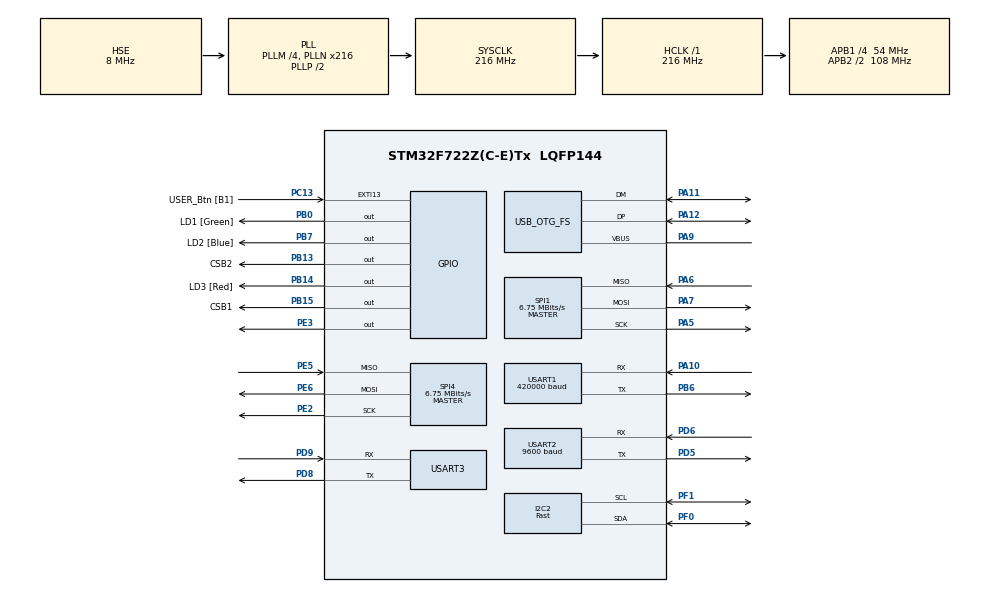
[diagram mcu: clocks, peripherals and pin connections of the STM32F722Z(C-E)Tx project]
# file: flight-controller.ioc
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CORTEX_M7.AccessPermission_S-Cortex_Memory_Protection_Unit_Region1_Settings_S=MPU_REGION_FULL_ACCESS
CORTEX_M7.BaseAddress_S-Cortex_Memory_Protection_Unit_Region1_Settings_S=0x2003C000
CORTEX_M7.CPU_DCache=Enabled
CORTEX_M7.CPU_ICache=Enabled
CORTEX_M7.DisableExec_S-Cortex_Memory_Protection_Unit_Region1_Settings_S=MPU_INSTRUCTION_ACCESS_DISABLE
CORTEX_M7.Enable_S-Cortex_Memory_Protection_Unit_Region1_Settings_S=MPU_REGION_ENABLE
CORTEX_M7.Enable_S-Cortex_Memory_Protection_Unit_Region2_Settings_S=__NULL
CORTEX_M7.IsShareable_S-Cortex_Memory_Protection_Unit_Region1_Settings_S=MPU_ACCESS_SHAREABLE
CORTEX_M7.Size_S-Cortex_Memory_Protection_Unit_Region1_Settings_S=MPU_REGION_SIZE_16KB
CORTEX_M7.TypeExtField_S-Cortex_Memory_Protection_Unit_Region1_Settings_S=MPU_TEX_LEVEL1
CORTEX_M7.default_mode_Activation=1
Dma.I2C2_RX.4.Direction=DMA_PERIPH_TO_MEMORY
Dma.I2C2_RX.4.FIFOMode=DMA_FIFOMODE_DISABLE
Dma.I2C2_RX.4.Instance=DMA1_Stream2
Dma.I2C2_RX.4.MemDataAlignment=DMA_MDATAALIGN_BYTE
Dma.I2C2_RX.4.MemInc=DMA_MINC_ENABLE
Dma.I2C2_RX.4.Mode=DMA_NORMAL
Dma.I2C2_RX.4.PeriphDataAlignment=DMA_PDATAALIGN_BYTE
Dma.I2C2_RX.4.PeriphInc=DMA_PINC_DISABLE
Dma.I2C2_RX.4.Priority=DMA_PRIORITY_LOW
Dma.I2C2_TX.5.Direction=DMA_MEMORY_TO_PERIPH
Dma.I2C2_TX.5.FIFOMode=DMA_FIFOMODE_DISABLE
Dma.I2C2_TX.5.Instance=DMA1_Stream7
Dma.I2C2_TX.5.MemDataAlignment=DMA_MDATAALIGN_BYTE
Dma.I2C2_TX.5.MemInc=DMA_MINC_ENABLE
Dma.I2C2_TX.5.Mode=DMA_NORMAL
Dma.I2C2_TX.5.PeriphDataAlignment=DMA_PDATAALIGN_BYTE
Dma.I2C2_TX.5.PeriphInc=DMA_PINC_DISABLE
Dma.I2C2_TX.5.Priority=DMA_PRIORITY_LOW
Dma.Request0=SPI1_RX
Dma.Request1=SPI1_TX
Dma.Request2=USART2_RX
Dma.Request3=USART2_TX
Dma.Request4=I2C2_RX
Dma.Request5=I2C2_TX
Dma.Request6=USART1_RX
Dma.SPI1_RX.0.Direction=DMA_PERIPH_TO_MEMORY
Dma.SPI1_RX.0.FIFOMode=DMA_FIFOMODE_DISABLE
Dma.SPI1_RX.0.Instance=DMA2_Stream0
Dma.SPI1_RX.0.MemDataAlignment=DMA_MDATAALIGN_BYTE
Dma.SPI1_RX.0.MemInc=DMA_MINC_ENABLE
Dma.SPI1_RX.0.Mode=DMA_NORMAL
Dma.SPI1_RX.0.PeriphDataAlignment=DMA_PDATAALIGN_BYTE
Dma.SPI1_RX.0.PeriphInc=DMA_PINC_DISABLE
Dma.SPI1_RX.0.Priority=DMA_PRIORITY_LOW
Dma.SPI1_TX.1.Direction=DMA_MEMORY_TO_PERIPH
Dma.SPI1_TX.1.FIFOMode=DMA_FIFOMODE_DISABLE
Dma.SPI1_TX.1.Instance=DMA2_Stream3
Dma.SPI1_TX.1.MemDataAlignment=DMA_MDATAALIGN_BYTE
Dma.SPI1_TX.1.MemInc=DMA_MINC_ENABLE
Dma.SPI1_TX.1.Mode=DMA_NORMAL
Dma.SPI1_TX.1.PeriphDataAlignment=DMA_PDATAALIGN_BYTE
Dma.SPI1_TX.1.PeriphInc=DMA_PINC_DISABLE
Dma.SPI1_TX.1.Priority=DMA_PRIORITY_LOW
Dma.USART1_RX.6.Direction=DMA_PERIPH_TO_MEMORY
Dma.USART1_RX.6.FIFOMode=DMA_FIFOMODE_DISABLE
Dma.USART1_RX.6.Instance=DMA2_Stream2
Dma.USART1_RX.6.MemDataAlignment=DMA_MDATAALIGN_BYTE
Dma.USART1_RX.6.MemInc=DMA_MINC_ENABLE
Dma.USART1_RX.6.Mode=DMA_CIRCULAR
Dma.USART1_RX.6.PeriphDataAlignment=DMA_PDATAALIGN_BYTE
Dma.USART1_RX.6.PeriphInc=DMA_PINC_DISABLE
Dma.USART1_RX.6.Priority=DMA_PRIORITY_LOW
Dma.USART2_RX.2.Direction=DMA_PERIPH_TO_MEMORY
Dma.USART2_RX.2.FIFOMode=DMA_FIFOMODE_DISABLE
Dma.USART2_RX.2.Instance=DMA1_Stream5
Dma.USART2_RX.2.MemDataAlignment=DMA_MDATAALIGN_BYTE
Dma.USART2_RX.2.MemInc=DMA_MINC_ENABLE
Dma.USART2_RX.2.Mode=DMA_CIRCULAR
Dma.USART2_RX.2.PeriphDataAlignment=DMA_PDATAALIGN_BYTE
Dma.USART2_RX.2.PeriphInc=DMA_PINC_DISABLE
Dma.USART2_RX.2.Priority=DMA_PRIORITY_LOW
Dma.USART2_TX.3.Direction=DMA_MEMORY_TO_PERIPH
Dma.USART2_TX.3.FIFOMode=DMA_FIFOMODE_DISABLE
Dma.USART2_TX.3.Instance=DMA1_Stream6
Dma.USART2_TX.3.MemDataAlignment=DMA_MDATAALIGN_BYTE
Dma.USART2_TX.3.MemInc=DMA_MINC_ENABLE
Dma.USART2_TX.3.Mode=DMA_NORMAL
Dma.USART2_TX.3.PeriphDataAlignment=DMA_PDATAALIGN_BYTE
Dma.USART2_TX.3.PeriphInc=DMA_PINC_DISABLE
Dma.USART2_TX.3.Priority=DMA_PRIORITY_LOW
I2C2.I2C_Speed_Mode=I2C_Fast
I2C2.Timing=0x6000030D
Mcu.Family=STM32F7
Mcu.Name=STM32F722Z(C-E)Tx
Mcu.Package=LQFP144
NVIC.DMA1_Stream2_IRQn=true\:5\:0\:true\:false\:true\:false\:true\:true
NVIC.DMA1_Stream5_IRQn=true\:5\:0\:true\:false\:true\:false\:true\:true
NVIC.DMA1_Stream6_IRQn=true\:5\:0\:true\:false\:true\:false\:true\:true
NVIC.DMA1_Stream7_IRQn=true\:0\:0\:false\:false\:true\:false\:true\:true
NVIC.DMA2_Stream0_IRQn=true\:5\:0\:true\:false\:true\:false\:true\:true
NVIC.DMA2_Stream2_IRQn=true\:5\:0\:true\:false\:true\:false\:true\:true
NVIC.DMA2_Stream3_IRQn=true\:5\:0\:true\:false\:true\:false\:true\:true
NVIC.I2C2_ER_IRQn=true\:5\:0\:true\:false\:true\:true\:true\:true
NVIC.I2C2_EV_IRQn=true\:5\:0\:true\:false\:true\:true\:true\:true
NVIC.OTG_FS_IRQn=true\:0\:0\:false\:false\:true\:false\:true\:true
NVIC.PriorityGroup=NVIC_PRIORITYGROUP_4
NVIC.SPI1_IRQn=true\:5\:0\:true\:false\:true\:true\:true\:true
NVIC.TIM6_DAC_IRQn=true\:15\:0\:false\:false\:true\:false\:true\:true
NVIC.TimeBase=TIM6_DAC_IRQn
NVIC.TimeBaseIP=TIM6
NVIC.USART1_IRQn=true\:5\:0\:true\:false\:true\:true\:true\:true
NVIC.USART2_IRQn=true\:5\:0\:true\:false\:true\:true\:true\:true
PA10.Mode=Asynchronous
PA10.Signal=USART1_RX
PA11.Mode=Device_Only
PA11.Signal=USB_OTG_FS_DM
PA12.Mode=Device_Only
PA12.Signal=USB_OTG_FS_DP
PA13.GPIO_Label=TMS
PA13.Mode=Serial_Wire
PA13.Signal=SYS_JTMS-SWDIO
PA14.GPIO_Label=TCK
PA14.Mode=Serial_Wire
PA14.Signal=SYS_JTCK-SWCLK
PA5.Mode=Full_Duplex_Master
PA5.Signal=SPI1_SCK
PA6.Mode=Full_Duplex_Master
PA6.Signal=SPI1_MISO
PA7.Mode=Full_Duplex_Master
PA7.Signal=SPI1_MOSI
PA9.Mode=Activate_VBUS
PA9.Signal=USB_OTG_FS_VBUS
PB0.GPIO_Label=LD1 [Green]
PB0.Signal=GPIO_Output
PB13.GPIO_Label=CSB2
PB13.GPIO_PuPd=GPIO_PULLUP
PB13.PinState=GPIO_PIN_RESET
PB13.Signal=GPIO_Output
PB14.GPIO_Label=LD3 [Red]
PB14.Signal=GPIO_Output
PB15.GPIO_Label=CSB1
PB15.GPIO_PuPd=GPIO_PULLUP
PB15.Signal=GPIO_Output
PB6.Mode=Asynchronous
PB6.Signal=USART1_TX
PB7.GPIO_Label=LD2 [Blue]
PB7.Signal=GPIO_Output
PC13.GPIO_Label=USER_Btn [B1]
PC13.Signal=GPXTI13
PC14-OSC32_IN.Mode=LSE-External-Oscillator
PC14-OSC32_IN.Signal=RCC_OSC32_IN
PC15-OSC32_OUT.Mode=LSE-External-Oscillator
PC15-OSC32_OUT.Signal=RCC_OSC32_OUT
PD5.Mode=Asynchronous
PD5.Signal=USART2_TX
PD6.Mode=Asynchronous
PD6.Signal=USART2_RX
PD8.Mode=Asynchronous
PD8.Signal=USART3_TX
PD9.Mode=Asynchronous
PD9.Signal=USART3_RX
PE2.Mode=Full_Duplex_Master
PE2.Signal=SPI4_SCK
PE3.Signal=GPIO_Output
PE5.Mode=Full_Duplex_Master
PE5.Signal=SPI4_MISO
PE6.Mode=Full_Duplex_Master
PE6.Signal=SPI4_MOSI
PF0.GPIO_Pu=GPIO_PULLUP
PF0.Mode=I2C
PF0.Signal=I2C2_SDA
PF1.GPIO_Pu=GPIO_PULLUP
PF1.Mode=I2C
PF1.Signal=I2C2_SCL
PH0-OSC_IN.GPIO_Label=MCO
PH0-OSC_IN.Mode=HSE-External-Clock-Source
PH0-OSC_IN.Signal=RCC_OSC_IN
PH1-OSC_OUT.Mode=HSE-External-Clock-Source
PH1-OSC_OUT.Signal=RCC_OSC_OUT
ProjectManager.HeapSize=0x200
ProjectManager.StackSize=0x400
ProjectManager.TargetToolchain=CMake
RCC.48MHZClocksFreq_Value=24000000
RCC.AHBFreq_Value=216000000
RCC.APB1CLKDivider=RCC_HCLK_DIV4
RCC.APB1Freq_Value=54000000
RCC.APB1TimFreq_Value=108000000
RCC.APB2CLKDivider=RCC_HCLK_DIV2
RCC.APB2Freq_Value=108000000
RCC.APB2TimFreq_Value=216000000
RCC.CortexFreq_Value=216000000
RCC.HCLKFreq_Value=216000000
RCC.HSE_VALUE=8000000
RCC.HSI_VALUE=16000000
RCC.PLLM=4
RCC.PLLMUL=RCC_PLL_MUL9
RCC.PLLN=216
RCC.PLLQ=9
RCC.PRESCALERUSB=RCC_USBCLKSOURCE_PLL_DIV1_5
RCC.SYSCLKFreq_VALUE=216000000
RCC.SYSCLKSource=RCC_SYSCLKSOURCE_PLLCLK
RCC.SYSCLKSourceVirtual=RCC_SYSCLKSOURCE_PLLCLK
RCC.USBFreq_Value=48000000
RCC.VCOOutputFreq_Value=432000000
SPI1.BaudRatePrescaler=SPI_BAUDRATEPRESCALER_16
SPI1.CalculateBaudRate=6.75 MBits/s
SPI1.DataSize=SPI_DATASIZE_8BIT
SPI1.Direction=SPI_DIRECTION_2LINES
SPI1.FirstBit=SPI_FIRSTBIT_MSB
SPI1.Mode=SPI_MODE_MASTER
SPI1.NSSPMode=SPI_NSS_PULSE_DISABLE
SPI1.VirtualType=VM_MASTER
SPI4.BaudRatePrescaler=SPI_BAUDRATEPRESCALER_16
SPI4.CalculateBaudRate=6.75 MBits/s
SPI4.DataSize=SPI_DATASIZE_8BIT
SPI4.Direction=SPI_DIRECTION_2LINES
SPI4.Mode=SPI_MODE_MASTER
SPI4.NSSPMode=SPI_NSS_PULSE_DISABLE
SPI4.VirtualType=VM_MASTER
USART1.BaudRate=420000
USART1.VirtualMode-Asynchronous=VM_ASYNC
USART2.BaudRate=9600
USART2.VirtualMode-Asynchronous=VM_ASYNC
USART3.VirtualMode-Asynchronous=VM_ASYNC
USB_DEVICE.CLASS_NAME_FS=CDC
USB_DEVICE.VirtualMode-CDC_FS=Cdc
USB_DEVICE.VirtualModeFS=Cdc_FS
USB_OTG_FS.VirtualMode=Device_Only
VP_SYS_VS_tim6.Mode=TIM6
VP_USB_DEVICE_VS_USB_DEVICE_CDC_FS.Mode=CDC_FS
board=NUCLEO-F722ZE

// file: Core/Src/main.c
/* USER CODE BEGIN Header */
/**
  ******************************************************************************
  * @file           : main.c
  * @brief          : Main program body
  ******************************************************************************
  * @attention
  *
  * Copyright (c) 2026 STMicroelectronics.
  * All rights reserved.
  *
  * This software is licensed under terms that can be found in the LICENSE file
  * in the root directory of this software component.
  * If no LICENSE file comes with this software, it is provided AS-IS.
  *
  ******************************************************************************
  */
/* USER CODE END Header */
#include "main.h"
#include "usb_device.h"

/* USER CODE BEGIN Includes */
#include "app_main.h"
#include "fc_types.h"
#include "pin_map.h"
/* USER CODE END Includes */

I2C_HandleTypeDef hi2c2;
DMA_HandleTypeDef hdma_i2c2_rx;
DMA_HandleTypeDef hdma_i2c2_tx;

SPI_HandleTypeDef hspi1;
SPI_HandleTypeDef hspi4;
DMA_HandleTypeDef hdma_spi1_rx;
DMA_HandleTypeDef hdma_spi1_tx;

UART_HandleTypeDef huart1;
UART_HandleTypeDef huart2;
UART_HandleTypeDef huart3;
DMA_HandleTypeDef hdma_usart1_rx;
DMA_HandleTypeDef hdma_usart2_rx;
DMA_HandleTypeDef hdma_usart2_tx;

/* USER CODE BEGIN PV */
static FC_Hw_t hw = {
  .hspi_imu = &hspi1,
  .hspi_bar = &hspi4,
  .hi2c_mag = &hi2c2,
  .huart_crsf = &huart1,
  .huart_gps = &huart2,
  .huart_print = &huart3,
};
/* USER CODE END PV */

void SystemClock_Config(void);
static void MPU_Config(void);
static void MX_GPIO_Init(void);
static void MX_DMA_Init(void);
static void MX_USART3_UART_Init(void);
static void MX_SPI1_Init(void);
static void MX_USART1_UART_Init(void);
static void MX_USART2_UART_Init(void);
static void MX_I2C2_Init(void);
static void MX_SPI4_Init(void);

int main(void)
{

  /* MPU Configuration--------------------------------------------------------*/
  MPU_Config();

  /* Enable the CPU Cache */

  /* Enable I-Cache---------------------------------------------------------*/
  SCB_EnableICache();

  /* Enable D-Cache---------------------------------------------------------*/
  SCB_EnableDCache();

  /* MCU Configuration--------------------------------------------------------*/

  /* Reset of all peripherals, Initializes the Flash interface and the Systick. */
  HAL_Init();

  /* Configure the system clock */
  SystemClock_Config();

  /* Initialize all configured peripherals */
  MX_GPIO_Init();
  MX_DMA_Init();
  MX_USART3_UART_Init();
  MX_SPI1_Init();
  MX_USART1_UART_Init();
  MX_USART2_UART_Init();
  MX_I2C2_Init();
  MX_SPI4_Init();
  MX_USB_DEVICE_Init();
  /* USER CODE BEGIN 2 */

  // Defining hardware peripherals for IMU
  if ( app_init(&hw) != FC_OK) Error_Handler() ;

  if ( app_start() != FC_OK) Error_Handler() ;
  /* USER CODE END 2 */

  /* Infinite loop */
  while (1)
  {

  }
}

void SystemClock_Config(void)
{
  RCC_OscInitTypeDef RCC_OscInitStruct = {0};
  RCC_ClkInitTypeDef RCC_ClkInitStruct = {0};

  /** Configure LSE Drive Capability
  */
  HAL_PWR_EnableBkUpAccess();

  /** Configure the main internal regulator output voltage
  */
  __HAL_RCC_PWR_CLK_ENABLE();
  __HAL_PWR_VOLTAGESCALING_CONFIG(PWR_REGULATOR_VOLTAGE_SCALE1);

  /** Initializes the RCC Oscillators according to the specified parameters
  * in the RCC_OscInitTypeDef structure.
  */
  RCC_OscInitStruct.OscillatorType = RCC_OSCILLATORTYPE_HSE;
  RCC_OscInitStruct.HSEState = RCC_HSE_BYPASS;
  RCC_OscInitStruct.PLL.PLLState = RCC_PLL_ON;
  RCC_OscInitStruct.PLL.PLLSource = RCC_PLLSOURCE_HSE;
  RCC_OscInitStruct.PLL.PLLM = 4;
  RCC_OscInitStruct.PLL.PLLN = 216;
  RCC_OscInitStruct.PLL.PLLP = RCC_PLLP_DIV2;
  RCC_OscInitStruct.PLL.PLLQ = 9;
  if (HAL_RCC_OscConfig(&RCC_OscInitStruct) != HAL_OK)
  {
    Error_Handler();
  }

  /** Activate the Over-Drive mode
  */
  if (HAL_PWREx_EnableOverDrive() != HAL_OK)
  {
    Error_Handler();
  }

  /** Initializes the CPU, AHB and APB buses clocks
  */
  RCC_ClkInitStruct.ClockType = RCC_CLOCKTYPE_HCLK|RCC_CLOCKTYPE_SYSCLK
                              |RCC_CLOCKTYPE_PCLK1|RCC_CLOCKTYPE_PCLK2;
  RCC_ClkInitStruct.SYSCLKSource = RCC_SYSCLKSOURCE_PLLCLK;
  RCC_ClkInitStruct.AHBCLKDivider = RCC_SYSCLK_DIV1;
  RCC_ClkInitStruct.APB1CLKDivider = RCC_HCLK_DIV4;
  RCC_ClkInitStruct.APB2CLKDivider = RCC_HCLK_DIV2;

  if (HAL_RCC_ClockConfig(&RCC_ClkInitStruct, FLASH_LATENCY_7) != HAL_OK)
  {
    Error_Handler();
  }
}

static void MX_I2C2_Init(void)
{

  hi2c2.Instance = I2C2;
  hi2c2.Init.Timing = 0x6000030D;
  hi2c2.Init.OwnAddress1 = 0;
  hi2c2.Init.AddressingMode = I2C_ADDRESSINGMODE_7BIT;
  hi2c2.Init.DualAddressMode = I2C_DUALADDRESS_DISABLE;
  hi2c2.Init.OwnAddress2 = 0;
  hi2c2.Init.OwnAddress2Masks = I2C_OA2_NOMASK;
  hi2c2.Init.GeneralCallMode = I2C_GENERALCALL_DISABLE;
  hi2c2.Init.NoStretchMode = I2C_NOSTRETCH_DISABLE;
  if (HAL_I2C_Init(&hi2c2) != HAL_OK)
  {
    Error_Handler();
  }

  /** Configure Analogue filter
  */
  if (HAL_I2CEx_ConfigAnalogFilter(&hi2c2, I2C_ANALOGFILTER_ENABLE) != HAL_OK)
  {
    Error_Handler();
  }

  /** Configure Digital filter
  */
  if (HAL_I2CEx_ConfigDigitalFilter(&hi2c2, 0) != HAL_OK)
  {
    Error_Handler();
  }

}

static void MX_SPI1_Init(void)
{

  /* SPI1 parameter configuration*/
  hspi1.Instance = SPI1;
  hspi1.Init.Mode = SPI_MODE_MASTER;
  hspi1.Init.Direction = SPI_DIRECTION_2LINES;
  hspi1.Init.DataSize = SPI_DATASIZE_8BIT;
  hspi1.Init.CLKPolarity = SPI_POLARITY_LOW;
  hspi1.Init.CLKPhase = SPI_PHASE_1EDGE;
  hspi1.Init.NSS = SPI_NSS_SOFT;
  hspi1.Init.BaudRatePrescaler = SPI_BAUDRATEPRESCALER_16;
  hspi1.Init.FirstBit = SPI_FIRSTBIT_MSB;
  hspi1.Init.TIMode = SPI_TIMODE_DISABLE;
  hspi1.Init.CRCCalculation = SPI_CRCCALCULATION_DISABLE;
  hspi1.Init.CRCPolynomial = 7;
  hspi1.Init.CRCLength = SPI_CRC_LENGTH_DATASIZE;
  hspi1.Init.NSSPMode = SPI_NSS_PULSE_DISABLE;
  if (HAL_SPI_Init(&hspi1) != HAL_OK)
  {
    Error_Handler();
  }

}

static void MX_SPI4_Init(void)
{

  /* SPI4 parameter configuration*/
  hspi4.Instance = SPI4;
  hspi4.Init.Mode = SPI_MODE_MASTER;
  hspi4.Init.Direction = SPI_DIRECTION_2LINES;
  hspi4.Init.DataSize = SPI_DATASIZE_8BIT;
  hspi4.Init.CLKPolarity = SPI_POLARITY_LOW;
  hspi4.Init.CLKPhase = SPI_PHASE_1EDGE;
  hspi4.Init.NSS = SPI_NSS_SOFT;
  hspi4.Init.BaudRatePrescaler = SPI_BAUDRATEPRESCALER_16;
  hspi4.Init.FirstBit = SPI_FIRSTBIT_MSB;
  hspi4.Init.TIMode = SPI_TIMODE_DISABLE;
  hspi4.Init.CRCCalculation = SPI_CRCCALCULATION_DISABLE;
  hspi4.Init.CRCPolynomial = 7;
  hspi4.Init.CRCLength = SPI_CRC_LENGTH_DATASIZE;
  hspi4.Init.NSSPMode = SPI_NSS_PULSE_DISABLE;
  if (HAL_SPI_Init(&hspi4) != HAL_OK)
  {
    Error_Handler();
  }

}

static void MX_USART1_UART_Init(void)
{

  huart1.Instance = USART1;
  huart1.Init.BaudRate = 420000;
  huart1.Init.WordLength = UART_WORDLENGTH_8B;
  huart1.Init.StopBits = UART_STOPBITS_1;
  huart1.Init.Parity = UART_PARITY_NONE;
  huart1.Init.Mode = UART_MODE_TX_RX;
  huart1.Init.HwFlowCtl = UART_HWCONTROL_NONE;
  huart1.Init.OverSampling = UART_OVERSAMPLING_16;
  huart1.Init.OneBitSampling = UART_ONE_BIT_SAMPLE_DISABLE;
  huart1.AdvancedInit.AdvFeatureInit = UART_ADVFEATURE_NO_INIT;
  if (HAL_UART_Init(&huart1) != HAL_OK)
  {
    Error_Handler();
  }

}

static void MX_USART2_UART_Init(void)
{

  huart2.Instance = USART2;
  huart2.Init.BaudRate = 9600;
  huart2.Init.WordLength = UART_WORDLENGTH_8B;
  huart2.Init.StopBits = UART_STOPBITS_1;
  huart2.Init.Parity = UART_PARITY_NONE;
  huart2.Init.Mode = UART_MODE_TX_RX;
  huart2.Init.HwFlowCtl = UART_HWCONTROL_NONE;
  huart2.Init.OverSampling = UART_OVERSAMPLING_16;
  huart2.Init.OneBitSampling = UART_ONE_BIT_SAMPLE_DISABLE;
  huart2.AdvancedInit.AdvFeatureInit = UART_ADVFEATURE_NO_INIT;
  if (HAL_UART_Init(&huart2) != HAL_OK)
  {
    Error_Handler();
  }

}

static void MX_USART3_UART_Init(void)
{

  huart3.Instance = USART3;
  huart3.Init.BaudRate = 115200;
  huart3.Init.WordLength = UART_WORDLENGTH_8B;
  huart3.Init.StopBits = UART_STOPBITS_1;
  huart3.Init.Parity = UART_PARITY_NONE;
  huart3.Init.Mode = UART_MODE_TX_RX;
  huart3.Init.HwFlowCtl = UART_HWCONTROL_NONE;
  huart3.Init.OverSampling = UART_OVERSAMPLING_16;
  huart3.Init.OneBitSampling = UART_ONE_BIT_SAMPLE_DISABLE;
  huart3.AdvancedInit.AdvFeatureInit = UART_ADVFEATURE_NO_INIT;
  if (HAL_UART_Init(&huart3) != HAL_OK)
  {
    Error_Handler();
  }

}

static void MX_DMA_Init(void)
{

  /* DMA controller clock enable */
  __HAL_RCC_DMA2_CLK_ENABLE();
  __HAL_RCC_DMA1_CLK_ENABLE();

  /* DMA interrupt init */
  /* DMA1_Stream2_IRQn interrupt configuration */
  HAL_NVIC_SetPriority(DMA1_Stream2_IRQn, 5, 0);
  HAL_NVIC_EnableIRQ(DMA1_Stream2_IRQn);
  /* DMA1_Stream5_IRQn interrupt configuration */
  HAL_NVIC_SetPriority(DMA1_Stream5_IRQn, 5, 0);
  HAL_NVIC_EnableIRQ(DMA1_Stream5_IRQn);
  /* DMA1_Stream6_IRQn interrupt configuration */
  HAL_NVIC_SetPriority(DMA1_Stream6_IRQn, 5, 0);
  HAL_NVIC_EnableIRQ(DMA1_Stream6_IRQn);
  /* DMA1_Stream7_IRQn interrupt configuration */
  HAL_NVIC_SetPriority(DMA1_Stream7_IRQn, 0, 0);
  HAL_NVIC_EnableIRQ(DMA1_Stream7_IRQn);
  /* DMA2_Stream0_IRQn interrupt configuration */
  HAL_NVIC_SetPriority(DMA2_Stream0_IRQn, 5, 0);
  HAL_NVIC_EnableIRQ(DMA2_Stream0_IRQn);
  /* DMA2_Stream2_IRQn interrupt configuration */
  HAL_NVIC_SetPriority(DMA2_Stream2_IRQn, 5, 0);
  HAL_NVIC_EnableIRQ(DMA2_Stream2_IRQn);
  /* DMA2_Stream3_IRQn interrupt configuration */
  HAL_NVIC_SetPriority(DMA2_Stream3_IRQn, 5, 0);
  HAL_NVIC_EnableIRQ(DMA2_Stream3_IRQn);

}

static void MX_GPIO_Init(void)
{
  GPIO_InitTypeDef GPIO_InitStruct = {0};

  /* GPIO Ports Clock Enable */
  __HAL_RCC_GPIOE_CLK_ENABLE();
  __HAL_RCC_GPIOC_CLK_ENABLE();
  __HAL_RCC_GPIOF_CLK_ENABLE();
  __HAL_RCC_GPIOH_CLK_ENABLE();
  __HAL_RCC_GPIOA_CLK_ENABLE();
  __HAL_RCC_GPIOB_CLK_ENABLE();
  __HAL_RCC_GPIOD_CLK_ENABLE();

  /*Configure GPIO pin Output Level */
  HAL_GPIO_WritePin(GPIOE, GPIO_PIN_3, GPIO_PIN_RESET);

  /*Configure GPIO pin Output Level */
  HAL_GPIO_WritePin(GPIOB, LD1_Pin|CSB2_Pin|LD3_Pin|CSB1_Pin
                          |LD2_Pin, GPIO_PIN_RESET);

  /*Configure GPIO pin : PE3 */
  GPIO_InitStruct.Pin = GPIO_PIN_3;
  GPIO_InitStruct.Mode = GPIO_MODE_OUTPUT_PP;
  GPIO_InitStruct.Pull = GPIO_NOPULL;
  GPIO_InitStruct.Speed = GPIO_SPEED_FREQ_LOW;
  HAL_GPIO_Init(GPIOE, &GPIO_InitStruct);

  /*Configure GPIO pin : USER_Btn_Pin */
  GPIO_InitStruct.Pin = USER_Btn_Pin;
  GPIO_InitStruct.Mode = GPIO_MODE_IT_RISING;
  GPIO_InitStruct.Pull = GPIO_NOPULL;
  HAL_GPIO_Init(USER_Btn_GPIO_Port, &GPIO_InitStruct);

  /*Configure GPIO pins : LD1_Pin LD3_Pin LD2_Pin */
  GPIO_InitStruct.Pin = LD1_Pin|LD3_Pin|LD2_Pin;
  GPIO_InitStruct.Mode = GPIO_MODE_OUTPUT_PP;
  GPIO_InitStruct.Pull = GPIO_NOPULL;
  GPIO_InitStruct.Speed = GPIO_SPEED_FREQ_LOW;
  HAL_GPIO_Init(GPIOB, &GPIO_InitStruct);

  /*Configure GPIO pins : CSB2_Pin CSB1_Pin */
  GPIO_InitStruct.Pin = CSB2_Pin|CSB1_Pin;
  GPIO_InitStruct.Mode = GPIO_MODE_OUTPUT_PP;
  GPIO_InitStruct.Pull = GPIO_PULLUP;
  GPIO_InitStruct.Speed = GPIO_SPEED_FREQ_LOW;
  HAL_GPIO_Init(GPIOB, &GPIO_InitStruct);

}

 /* MPU Configuration */

void MPU_Config(void)
{
  MPU_Region_InitTypeDef MPU_InitStruct = {0};

  /* Disables the MPU */
  HAL_MPU_Disable();

  /** Initializes and configures the Region and the memory to be protected
  */
  MPU_InitStruct.Enable = MPU_REGION_ENABLE;
  MPU_InitStruct.Number = MPU_REGION_NUMBER0;
  MPU_InitStruct.BaseAddress = 0x0;
  MPU_InitStruct.Size = MPU_REGION_SIZE_4GB;
  MPU_InitStruct.SubRegionDisable = 0x87;
  MPU_InitStruct.TypeExtField = MPU_TEX_LEVEL0;
  MPU_InitStruct.AccessPermission = MPU_REGION_NO_ACCESS;
  MPU_InitStruct.DisableExec = MPU_INSTRUCTION_ACCESS_DISABLE;
  MPU_InitStruct.IsShareable = MPU_ACCESS_SHAREABLE;
  MPU_InitStruct.IsCacheable = MPU_ACCESS_NOT_CACHEABLE;
  MPU_InitStruct.IsBufferable = MPU_ACCESS_NOT_BUFFERABLE;

  HAL_MPU_ConfigRegion(&MPU_InitStruct);

  /** Initializes and configures the Region and the memory to be protected
  */
  MPU_InitStruct.Number = MPU_REGION_NUMBER1;
  MPU_InitStruct.BaseAddress = 0x2003C000;
  MPU_InitStruct.Size = MPU_REGION_SIZE_16KB;
  MPU_InitStruct.SubRegionDisable = 0x0;
  MPU_InitStruct.TypeExtField = MPU_TEX_LEVEL1;
  MPU_InitStruct.AccessPermission = MPU_REGION_FULL_ACCESS;

  HAL_MPU_ConfigRegion(&MPU_InitStruct);
  /* Enables the MPU */
  HAL_MPU_Enable(MPU_PRIVILEGED_DEFAULT);

}

void HAL_TIM_PeriodElapsedCallback(TIM_HandleTypeDef *htim)
{
  if (htim->Instance == TIM6)
  {
    HAL_IncTick();
  }
}

void Error_Handler(void)
{
  __disable_irq();
  while (1)
  {
  }
}
